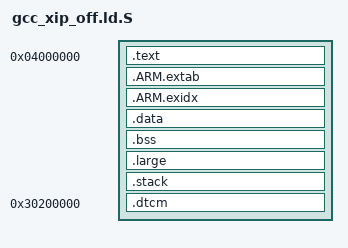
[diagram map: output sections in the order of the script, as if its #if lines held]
/* Linker script to place sections and symbol values. Should be used together
 * with other linker script that defines memory regions FLASH and RAM.
 * It references following symbols, which must be defined in code:
 *   Reset_Handler : Entry of reset handler
 *
 * It defines following symbols, which code can use without definition:
 *   __exidx_start
 *   __exidx_end
 *   __copy_table_start__
 *   __copy_table_end__
 *   __zero_table_start__
 *   __zero_table_end__
 *   __etext
 *   __data_start__
 *   __preinit_array_start
 *   __preinit_array_end
 *   __init_array_start
 *   __init_array_end
 *   __fini_array_start
 *   __fini_array_end
 *   __data_end__
 *   __bss_start__
 *   __bss_end__
 *   __end__
 *   end
 *   __HeapLimit
 *   __StackLimit
 *   __StackTop
 *   __stack
 */
#include "rtconfig.h"

ENTRY(Reset_Handler)
_ram_fs_size = 0x10000;
_system_stack_size = 0x400;
_code_start_addr = 0x04000000;
_data_start_off  = 0x1c000000;
_dtcm_start_addr = 0x30200000;
_dtcm_heap_size  = 0x80000;

PROVIDE(xSramDataBase  = _code_start_addr + _data_start_off );
PROVIDE(xSramBase  = _code_start_addr );
PROVIDE(xSramSize  = 0x100000 );

SECTIONS
{
    . = _code_start_addr;
    _stext = .;
    _stext_ext = .;
    .text :
    {
        . = ALIGN(4);
        KEEP(*(.vectors))            /* Startup code */
        . = ALIGN(4);
        *(.text)                        /* remaining code */
        *(.text.*)                      /* remaining code */
        *(.rodata)                      /* read-only data (constants) */
        *(.rodata*)
        *(.glue_7)
        *(.glue_7t)
        *(.gnu.linkonce.t*)

        . = ALIGN(4);
        PROVIDE(__ctors_start__ = .);
        /* old GCC version uses .ctors */
        KEEP(*(SORT(.ctors.*)))
        KEEP(*(.ctors))
        /* new GCC version uses .init_array */
        KEEP (*(SORT(.init_array.*)))
        KEEP (*(.init_array))
        PROVIDE(__ctors_end__ = .);

        /* section information for finsh shell */
        . = ALIGN(4);
        __fsymtab_start = .;
        KEEP(*(FSymTab))
        __fsymtab_end = .;
        . = ALIGN(4);
        __vsymtab_start = .;
        KEEP(*(VSymTab))
        __vsymtab_end = .;
        . = ALIGN(4);

        /* section information for initial. */
        . = ALIGN(4);
        __rt_init_start = .;
        KEEP(*(SORT(.rti_fn*)))
        __rt_init_end = .;
        . = ALIGN(4);

         /* section information for modules */
        . = ALIGN(4);
        __rtmsymtab_start = .;
        KEEP(*(RTMSymTab))
        __rtmsymtab_end = .;
        . = ALIGN(4);
    }

    .ARM.extab :
    {
        *(.ARM.extab* .gnu.linkonce.armextab.*)
    }

    __exidx_start = .;
    .ARM.exidx :
    {
        *(.ARM.exidx* .gnu.linkonce.armexidx.*)
        /* This is used by the startup in order to initialize the .data secion */
        _sidata = .;
    }
    __exidx_end = .;

    /* To copy multiple ROM to RAM sections,
     * uncomment .copy.table section and,
     * define __STARTUP_COPY_MULTIPLE in startup_ARMCMx.S */
    /*
    .copy.table :
    {
        . = ALIGN(4);
        __copy_table_start__ = .;
        LONG (__etext)
        LONG (__data_start__)
        LONG (__data_end__ - __data_start__)
        LONG (__etext2)
        LONG (__data2_start__)
        LONG (__data2_end__ - __data2_start__)
        __copy_table_end__ = .;
    }
    */

    /* To clear multiple BSS sections,
     * uncomment .zero.table section and,
     * define __STARTUP_CLEAR_BSS_MULTIPLE in startup_ARMCMx.S */
    /*
    .zero.table :
    {
        . = ALIGN(4);
        __zero_table_start__ = .;
        LONG (__bss_start__)
        LONG (__bss_end__ - __bss_start__)
        LONG (__bss2_start__)
        LONG (__bss2_end__ - __bss2_start__)
        __zero_table_end__ = .;
    }
    */

    /* must be cacheline align */
    __etext = ALIGN (32);
    _etext = .;
    _etext_ext = .;

    . = _data_start_off + __etext;
    .data : AT (__etext)
    {
        __data_start__ = .;
        *(vtable)
        *(.data*)

        . = ALIGN(4);
        PROVIDE(__dtors_start__ = .);
        KEEP(*(SORT(.dtors.*)))
        KEEP(*(.dtors))
        PROVIDE(__dtors_end__ = .);

        . = ALIGN(4);
        /* preinit data */
        PROVIDE_HIDDEN (__preinit_array_start = .);
        KEEP(*(.preinit_array))
        PROVIDE_HIDDEN (__preinit_array_end = .);

        . = ALIGN(4);
        /* init data */
        PROVIDE_HIDDEN (__init_array_start = .);
        KEEP(*(SORT(.init_array.*)))
        KEEP(*(.init_array))
        PROVIDE_HIDDEN (__init_array_end = .);


        . = ALIGN(4);
        /* finit data */
        PROVIDE_HIDDEN (__fini_array_start = .);
        KEEP(*(SORT(.fini_array.*)))
        KEEP(*(.fini_array))
        PROVIDE_HIDDEN (__fini_array_end = .);

        KEEP(*(.jcr*))
        . = ALIGN(4);
        /* All data end */
        __data_end__ = .;

    }

    .bss :
    {
        . = ALIGN(4);
        __bss_start__ = .;
        *(.bss*)
        *(COMMON)
        . = ALIGN(4);
        __bss_end__ = .;
    }

    /* region for ramfs, enable if you need */
    /*.ramfs :
    {
        . = ALIGN(4);
        __ramfs_start__ = .;
        . = . + _ram_fs_size;
        __ramfs_end__ = .;
    }*/

    /* region for large memory allocate */
#ifdef RT_LARGE_HEAP_SIZE
    .large :
    {
        . = ALIGN(4);
        __large_start__ = .;
        . = . + RT_LARGE_HEAP_SIZE;
        __large_end__ = .;
    }
#endif

    .stack :
    {
        . = ALIGN(4);
        _sstack = .;
        . = . + _system_stack_size;
        _estack = .;
        . = ALIGN(4);
        PROVIDE(__StackTop = .);
    }

    __heap_start__ = .;

#ifdef RT_USING_DTCM_HEAP
    /* region for dtcm memory allocate */
    . = _dtcm_start_addr;
    .dtcm (NOLOAD):
    {
        . = ALIGN(4);
        __dtcm_start__ = .;
        . = . + _dtcm_heap_size;
        __dtcm_end__ = .;
    }
#endif
}
